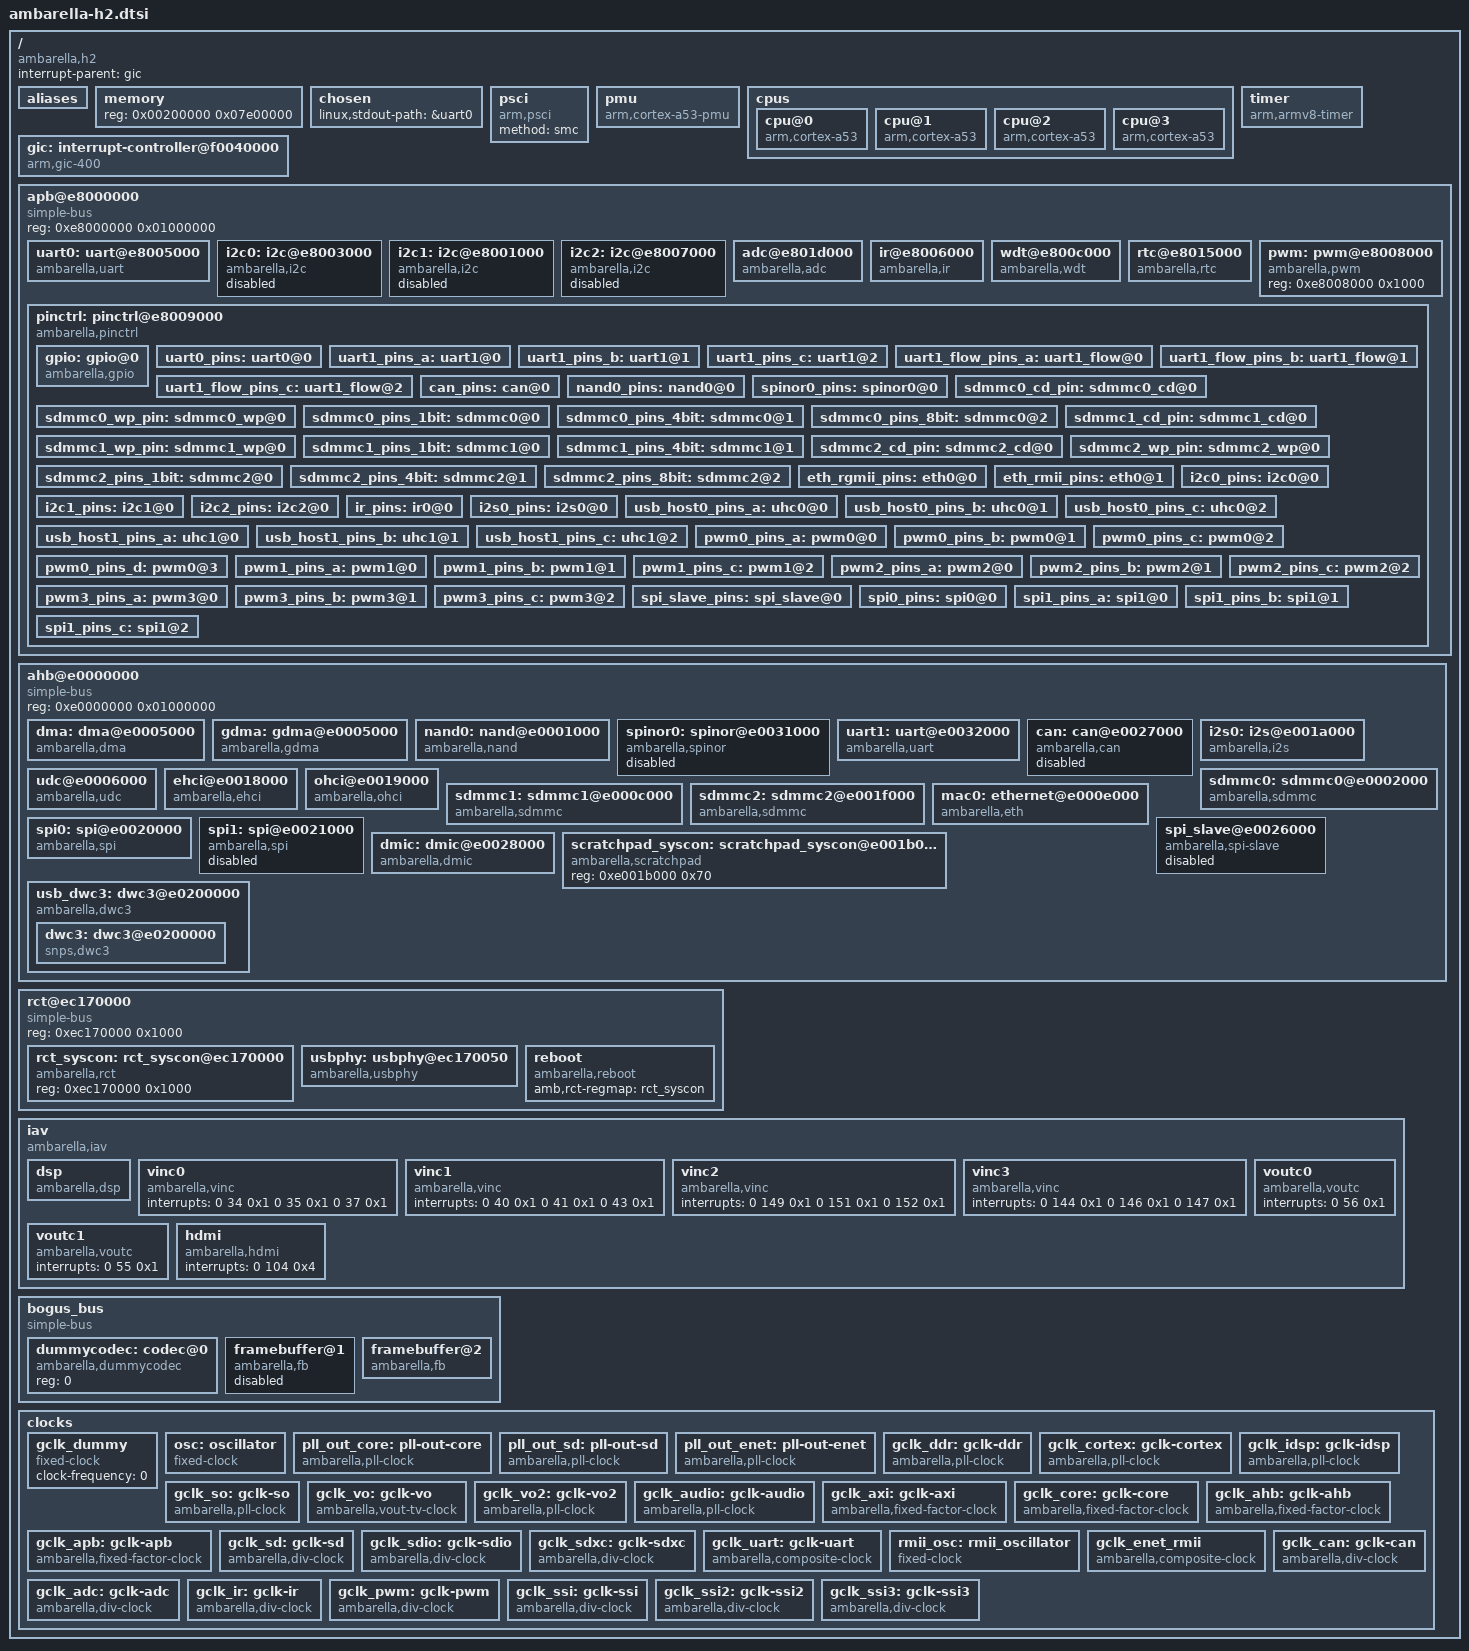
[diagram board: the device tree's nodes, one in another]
/*
 * Copyright (C) 2013 Ambarella,Inc. - http://www.ambarella.com/
 * Author: Cao Rongrong <rrcao@ambarella.com>
 *
 * This program is free software; you can redistribute it and/or modify
 * it under the terms of the GNU General Public License version 2 as
 * published by the Free Software Foundation.
 */

/ {
	compatible = "ambarella,h2";
	interrupt-parent = <&gic>;
	#address-cells = <1>;
	#size-cells = <1>;

	aliases {
		serial0 = &uart0;
		serial1 = &uart1;
		nand = &nand0;
		spinor = &spinor0;
		sd0 = &sdmmc0;
		sd1 = &sdmmc1;
		sd2 = &sdmmc2;
		i2c0 = &i2c0;
		i2c1 = &i2c1;
		i2c2 = &i2c2;
		spi0 = &spi0;
		spi1 = &spi1;
		ethernet0 = &mac0;
	};

	/* the memory node will be overwritten in Amboot,
	 * here is just the default value. */
	memory {
		device_type = "memory";
		reg = <0x00200000 0x07e00000>; /* 126M */
	};

	chosen {
		linux,stdout-path = &uart0;
	};

	psci {
		compatible = "arm,psci";
		method = "smc";
	};

	pmu {
		compatible = "arm,cortex-a53-pmu";
		interrupts = <0 15 0x4>,
			     <0 31 0x4>,
			     <0 114 0x4>,
			     <0 115 0x4>;
	};

	cpus {
		#address-cells = <1>;
		#size-cells = <0>;
		amb,core-div = <1>;
		clock-latency = <100000>;
		/* the highest frequency is gotten in runtime */
		cpufreq_tbl = < /*core_clk	cortex_clk*/
				24000		96000
				108000		504000>;

		cpu@0 {
			compatible = "arm,cortex-a53", "arm,armv8";
			device_type = "cpu";
			reg = <0x0>;
			enable-method = "spin-table";
			cpu-release-addr = <0 0x00000000>;
		};

		cpu@1 {
			compatible = "arm,cortex-a53", "arm,armv8";
			device_type = "cpu";
			reg = <0x1>;
			enable-method = "spin-table";
			cpu-release-addr = <0 0x00000000>;
		};

		cpu@2 {
			compatible = "arm,cortex-a53", "arm,armv8";
			device_type = "cpu";
			reg = <0x2>;
			enable-method = "spin-table";
			cpu-release-addr = <0 0x00000000>;
		};

		cpu@3 {
			compatible = "arm,cortex-a53", "arm,armv8";
			device_type = "cpu";
			reg = <0x3>;
			enable-method = "spin-table";
			cpu-release-addr = <0 0x00000000>;
		};
	};

	gic: interrupt-controller@f0040000 {
		compatible = "arm,gic-400";
		#interrupt-cells = <3>;
		#address-cells = <0>;
		interrupt-controller;
		reg = <0xf0041000 0x1000>,	/* GIC Dist */
		      <0xf0042000 0x2000>,	/* GIC CPU */
		      /* following are not used if no virtulization
		      <0xf0044000 0x2000>,	/* GIC VCPU Control */
		      <0xf0046000 0x2000>;	/* GIC VCPU */
		interrupts = <1 9 0xf04>;	/* GIC Maintenence IRQ */
	};

	timer {
		compatible = "arm,armv8-timer";
		interrupts = <1 13 0xf08>,	/* Secure Phys IRQ */
			     <1 14 0xf08>,	/* Non-secure Phys IRQ */
			     <1 11 0xf08>,	/* Virt IRQ */
			     <1 10 0xf08>;	/* Hyp IRQ */
	};

	apb@e8000000 {	/* APB */
		compatible = "simple-bus";
		#address-cells = <1>;
		#size-cells = <1>;
		reg = <0xe8000000 0x01000000>;
		ranges;

		uart0: uart@e8005000 {
			compatible = "ambarella,uart";
			reg = <0xe8005000 0x1000>;
			interrupts = <0 108 0x4>;
			pinctrl-names = "default";
			pinctrl-0 = <&uart0_pins>;
			clocks = <&gclk_uart>;
			status = "ok";
			/* amb,tx-fifo-fix; */
		};

		i2c0: i2c@e8003000 {
			compatible = "ambarella,i2c";
			#address-cells = <1>;
			#size-cells = <0>;
			reg = <0xe8003000 0x1000>;
			interrupts = <0 85 0x4>;
			pinctrl-names = "default";
			pinctrl-0 = <&i2c0_pins>;
			clocks = <&gclk_apb>;
			clock-frequency = <100000>;
			amb,i2c-class = <0x81>;
			status = "disabled";
	        };

		i2c1: i2c@e8001000 {
			compatible = "ambarella,i2c";
			#address-cells = <1>;
			#size-cells = <0>;
			reg = <0xe8001000 0x1000>;
			interrupts = <0 84 0x4>;
			pinctrl-names = "default";
			pinctrl-0 = <&i2c1_pins>;
			clocks = <&gclk_apb>;
			clock-frequency = <100000>;
			amb,i2c-class = <0x08>;
			status = "disabled";
	        };

		i2c2: i2c@e8007000 {
			compatible = "ambarella,i2c";
			#address-cells = <1>;
			#size-cells = <0>;
			reg = <0xe8007000 0x1000>;
			interrupts = <0 83 0x4>;
			pinctrl-names = "default";
			clocks = <&gclk_apb>;
			pinctrl-0 = <&i2c2_pins>;
			clock-frequency = <100000>;
			amb,i2c-class = <0x81>;
			status = "disabled";
	        };

		adc@e801d000 {
			compatible = "ambarella,adc";
			reg = <0xe801d000 0x1000>;
			interrupts = <0 103 0x4>;
			clock-frequency = <3000000>;
			clocks = <&gclk_adc>;
			amb,rct-regmap = <&rct_syscon>;
			amb,scaler-1v8 = <0x01>;
			amb,t2v-channel = <4>;
		};

		ir@e8006000 {
			compatible = "ambarella,ir";
			reg = <0xe8006000 0x1000>;
			interrupts = <0 86 0x4>;
			pinctrl-names = "default";
			pinctrl-0 = <&ir_pins>;
			clocks = <&gclk_ir>;
		};

		wdt@e800c000 {
			compatible = "ambarella,wdt";
			reg = <0xe800c000 0x1000>;
			amb,rct-regmap = <&rct_syscon>;
			/* interrupts = <0 105 0x4>; */
			timeout-sec = <15>;
		};

		rtc@e8015000 {
			compatible = "ambarella,rtc";
			reg = <0xe8015000 0x1000>;
			interrupts = <0 157 0x1>;
		};

		pwm: pwm@e8008000 {
			compatible = "ambarella,pwm";
			reg = <0xe8008000 0x1000>;
			#pwm-cells = <3>;
		};

		pinctrl: pinctrl@e8009000 {
			compatible = "ambarella,pinctrl", "simple-bus";
			#address-cells = <1>;
			#size-cells = <0>;
			reg = <0xe8009000 0x1000>,
			      <0xe800a000 0x1000>,
			      <0xe800e000 0x1000>,
			      <0xe8010000 0x1000>,
			      <0xe8011000 0x1000>,
			      <0xe8016000 0x1000>,
			      <0xe8015080 0x24>,
			      <0xec170314 0x20>;
			reg-names = "gpio0", "gpio1", "gpio2", "gpio3", "gpio4",
				    "iomux", "pad", "ds";
			#gpio-range-cells = <3>;

			gpio: gpio@0 {
				compatible = "ambarella,gpio";
				/* gpio interrupts to gic */
				interrupts = <0 124 0x4>,
					     <0 123 0x4>,
					     <0 122 0x4>,
					     <0 121 0x4>,
					     <0 120 0x4>;
				gpio-controller;
				#gpio-cells = <2>;
				gpio-ranges = <&pinctrl 0 0 160>;
				interrupt-controller;
				#interrupt-cells = <2>;
			};

			uart0_pins: uart0@0 {
				reg = <0>;
				amb,pinmux-ids = <0x101f 0x1020>;
			};

			uart1_pins_a: uart1@0 {
				reg = <0>;
				amb,pinmux-ids = <0x2008 0x2009>;
			};

			uart1_pins_b: uart1@1 {
				reg = <1>;
				amb,pinmux-ids = <0x301a 0x3017>;
			};

			uart1_pins_c: uart1@2 {
				reg = <2>;
				amb,pinmux-ids = <0x107b 0x107c>;
			};

			uart1_flow_pins_a: uart1_flow@0 {
				reg = <0>;
				amb,pinmux-ids = <0x200a 0x200b>;
			};

			uart1_flow_pins_b: uart1_flow@1 {
				reg = <1>;
				amb,pinmux-ids = <0x3018 0x3019>;
			};

			uart1_flow_pins_c: uart1_flow@2 {
				reg = <2>;
				amb,pinmux-ids = <0x107d 0x107e>;
			};

			can_pins: can@0 {
				reg = <0>;
				amb,pinmux-ids = <0x307d 0x307e>;
			};

			nand0_pins: nand0@0 {
				reg = <0>;
				amb,pinmux-ids = <0x2038 0x2039 0x203a 0x203f
						  0x2040 0x2041 0x2042 0x2043
						  0x2044 0x2045 0x2046 0x2047
						  0x2048 0x2049 0x204a>;
			};

			spinor0_pins: spinor0@0 {
				reg = <0>;
				amb,pinmux-ids = <0x3039 0x303a 0x303f 0x3040
						  0x3041 0x3042 0x3043 0x3044
						  0x3045 0x3046 0x3047 0x3048
						  0x3049>;
			};

			sdmmc0_cd_pin: sdmmc0_cd@0 {
				reg = <0>;
				amb,pinmux-ids = <0x203d>;
			};

			sdmmc0_wp_pin: sdmmc0_wp@0 {
				reg = <0>;
				amb,pinmux-ids = <0x203e>;
			};

			sdmmc0_pins_1bit: sdmmc0@0 {
				reg = <0>;
				amb,pinmux-ids = <0x203b 0x203c 0x204b>;
			};

			sdmmc0_pins_4bit: sdmmc0@1 {
				reg = <1>;
				amb,pinmux-ids = <0x203b 0x203c 0x204b
						  0x204c 0x204d 0x204e>;
			};

			sdmmc0_pins_8bit: sdmmc0@2 {
				reg = <2>;
				amb,pinmux-ids = <0x203b 0x203c 0x204b 0x204c 0x204d
						  0x204e 0x204f 0x2050 0x2051 0x2052>;
			};

			sdmmc1_cd_pin: sdmmc1_cd@0 {
				reg = <0>;
				amb,pinmux-ids = <0x5002>;
			};

			sdmmc1_wp_pin: sdmmc1_wp@0 {
				reg = <0>;
				amb,pinmux-ids = <0x5003>;
			};

			sdmmc1_pins_1bit: sdmmc1@0 {
				reg = <0>;
				amb,pinmux-ids = <0x5000 0x5001 0x5004>;
			};

			sdmmc1_pins_4bit: sdmmc1@1 {
				reg = <1>;
				amb,pinmux-ids = <0x5000 0x5001 0x5004
						  0x5005 0x5006 0x5007>;
			};

			sdmmc2_cd_pin: sdmmc2_cd@0 {
				reg = <0>;
				amb,pinmux-ids = <0x2059>;
			};

			sdmmc2_wp_pin: sdmmc2_wp@0 {
				reg = <0>;
				amb,pinmux-ids = <0x205a>;
			};

			sdmmc2_pins_1bit: sdmmc2@0 {
				reg = <0>;
				amb,pinmux-ids = <0x2053 0x2054 0x2055>;
			};

			sdmmc2_pins_4bit: sdmmc2@1 {
				reg = <1>;
				amb,pinmux-ids = <0x2053 0x2054 0x2055
						  0x2056 0x2057 0x2058>;
			};

			sdmmc2_pins_8bit: sdmmc2@2 {
				reg = <2>;
				amb,pinmux-ids = <0x2053 0x2054 0x2055 0x2056 0x2057
						  0x2058 0x205b 0x205c 0x205d 0x205e>;
			};

			eth_rgmii_pins: eth0@0 {
				reg = <0>;
				amb,pinmux-ids = <0x4032 0x4033 0x4034 0x4035
						  0x4036 0x4037 0x4026 0x4030
						  0x4028 0x4029 0x402a 0x402b
						  0x402c 0x402d 0x402e 0x402f>;
			};

			eth_rmii_pins: eth0@1 {
				reg = <1>;
				amb,pinmux-ids = <0x3032 0x3033 0x3035 0x3034
					0x3036 0x3037 0x3026 0x3030
					0x3028 0x3029 0x302c 0x302d>;
			};

			i2c0_pins: i2c0@0 {
				reg = <0>;
				amb,pinmux-ids = <0x100f 0x1010>;
			};

			i2c1_pins: i2c1@0 {
				reg = <0>;
				amb,pinmux-ids = <0x1011 0x1012>;
			};

			i2c2_pins: i2c2@0 {
				reg = <0>;
				amb,pinmux-ids = <0x1013 0x1014>;
			};

			ir_pins: ir0@0 {
				reg = <0>;
				amb,pinmux-ids = <0x1015>;
			};

			i2s0_pins: i2s0@0 {
				reg = <0>;
				amb,pinmux-ids = <0x1021 0x1022 0x1023 0x1024 0x1025>;
			};

			usb_host0_pins_a: uhc0@0 { /* USB0: host/device configurable */
				reg = <0>;
				amb,pinmux-ids = <0x3008 0x300a>;
			};

			usb_host0_pins_b: uhc0@1 { /* USB0: host/device configurable */
				reg = <1>;
				amb,pinmux-ids = <0x301b 0x301d>;
			};

			usb_host0_pins_c: uhc0@2 { /* USB0: host/device configurable */
				reg = <2>;
				amb,pinmux-ids = <0x505b 0x505d>;
			};

			usb_host1_pins_a: uhc1@0 { /* USB1: host only */
				reg = <0>;
				amb,pinmux-ids = <0x3009 0x300b>;
			};

			usb_host1_pins_b: uhc1@1 { /* USB1: host only */
				reg = <1>;
				amb,pinmux-ids = <0x301c 0x301e>;
			};

			usb_host1_pins_c: uhc1@2 { /* USB1: host only */
				reg = <2>;
				amb,pinmux-ids = <0x505c 0x505e>;
			};

			pwm0_pins_a: pwm0@0 {
				reg = <0>;
				amb,pinmux-ids = <0x3000>;
			};

			pwm0_pins_b: pwm0@1 {
				reg = <1>;
				amb,pinmux-ids = <0x5008>;
			};

			pwm0_pins_c: pwm0@2 {
				reg = <2>;
				amb,pinmux-ids = <0x5028>;
			};

			pwm0_pins_d: pwm0@3 {
				reg = <3>;
				amb,pinmux-ids = <0x107a>;
			};

			pwm1_pins_a: pwm1@0 {
				reg = <0>;
				amb,pinmux-ids = <0x3001>;
			};

			pwm1_pins_b: pwm1@1 {
				reg = <1>;
				amb,pinmux-ids = <0x5009>;
			};

			pwm1_pins_c: pwm1@2 {
				reg = <2>;
				amb,pinmux-ids = <0x5029>;
			};

			pwm2_pins_a: pwm2@0 {
				reg = <0>;
				amb,pinmux-ids = <0x3002>;
			};

			pwm2_pins_b: pwm2@1 {
				reg = <1>;
				amb,pinmux-ids = <0x500a>;
			};

			pwm2_pins_c: pwm2@2 {
				reg = <2>;
				amb,pinmux-ids = <0x502a>;
			};

			pwm3_pins_a: pwm3@0 {
				reg = <0>;
				amb,pinmux-ids = <0x3003>;
			};

			pwm3_pins_b: pwm3@1 {
				reg = <1>;
				amb,pinmux-ids = <0x500b>;
			};

			pwm3_pins_c: pwm3@2 {
				reg = <2>;
				amb,pinmux-ids = <0x502b>;
			};

			spi_slave_pins: spi_slave@0 {
				reg = <0>;
				amb,pinmux-ids = <0x101b 0x101c 0x101d 0x101e>;
			};

			spi0_pins: spi0@0 {
				reg = <0>;
				amb,pinmux-ids = <0x1016 0x1017 0x1018>;
			};

			spi1_pins_a: spi1@0 {
				reg = <0>;
				amb,pinmux-ids = <0x2000 0x2001 0x2002>;
			};

			spi1_pins_b: spi1@1 {
				reg = <1>;
				amb,pinmux-ids = <0x201b 0x201c 0x201d>;
			};

			spi1_pins_c: spi1@2 {
				reg = <2>;
				amb,pinmux-ids = <0x207b 0x207c 0x207d>;
			};
		};
	};

	ahb@e0000000 {	/* AHB */
		compatible = "simple-bus";
		#address-cells = <1>;
		#size-cells = <1>;
		reg = <0xe0000000 0x01000000>;
		ranges;

		dma: dma@e0005000 {
			compatible = "ambarella,dma";
			reg = <0xe0005000 0x1000>;
			interrupts = <0 69 0x4>;
			#dma-cells = <1>;
			dma-channels = <8>;
			dma-requests = <14>;
			amb,scr-regmap = <&scratchpad_syscon>;
			/* support pause/resume/stop */
			amb,support-prs;
		};

		gdma: gdma@e0005000 {
			compatible = "ambarella,gdma";
			reg = <0xe0015000 0x400>;
			interrupts = <0 74 0x1>;
		};

		nand0: nand@e0001000 {
			compatible = "ambarella,nand";
			#address-cells = <1>;
			#size-cells = <1>;
			reg = <0xe0001000 0x1000>,	/* fio reg address */
			      <0xe0012000 0x1000>,	/* fdma reg address */
			      <0xe0000000 0x4>;		/* fifo base */
			interrupts = <0 72 0x4>,	/* fio_cmd_irq */
				     <0 73 0x4>,	/* fio_dma_irq */
				     <0 70 0x4>;	/* fdma_irq */
			amb,rct-regmap = <&rct_syscon>;
			pinctrl-names = "default";
			pinctrl-0 = <&nand0_pins>;
			clocks = <&gclk_core>;
			nand-on-flash-bbt;
			amb,enable-wp;
			/* amb,soft-ecc = <1>; */
		};

		spinor0: spinor@e0031000 {
			compatible = "ambarella,spinor";
			reg = <0xe0031000 0x2ff>, /* spi nor controller */
			      <0xe0005300 0x20>;  /* dma reg */
			pinctrl-names = "default";
			pinctrl-0 = <&spinor0_pins>;
			status = "disabled";
		};

		uart1: uart@e0032000 {
			compatible = "ambarella,uart";
			reg = <0xe0032000 0x1000>;
			interrupts = <0 82 0x4>;
			pinctrl-names = "default";
			pinctrl-0 = <&uart1_pins_c &uart1_flow_pins_c>;
			clocks = <&gclk_uart>;
			status = "ok";
			amb,msr-used;	/* use Modem Status Register */
			amb,txdma-used;
			amb,rxdma-used;
			/* amb,tx-fifo-fix; */
			/* need to select pinctrl setup in board dts */
		};

		can: can@e0027000 {
			compatible = "ambarella,can";
			reg = <0xe0027000 0xc00>;
			interrupts = <0 64 0x4>;
			pinctrl-names = "default";
			pinctrl-0 = <&can_pins>;
			clocks = <&gclk_can>;
			status = "disabled";
		};

		i2s0: i2s@e001a000 {
			compatible = "ambarella,i2s";
			#sound-dai-cells = <0>;
			reg = <0xe001a000 0x1000>;
			pinctrl-names = "default";
			pinctrl-0 = <&i2s0_pins>;
			amb,i2s-channels = <2>;
			amb,default-mclk = <12288000>;
			dmas = <&dma 10>, <&dma 11>;
			dma-names = "tx", "rx";
		};

		udc@e0006000 {
			compatible = "ambarella,udc";
			reg = <0xe0006000 0x2000>;
			interrupts = <0 68 0x4>;
			amb,rct-regmap = <&rct_syscon>;
			amb,scr-regmap = <&scratchpad_syscon>;
			amb,usbphy = <&usbphy>;
		};

		ehci@e0018000 {
			compatible = "ambarella,ehci";
			reg = <0xe0018000 0x1000>;
			interrupts = <0 66 0x4>;
			amb,usbphy = <&usbphy>;
		};

		ohci@e0019000 {
			compatible = "ambarella,ohci";
			reg = <0xe0019000 0x1000>;
			interrupts = <0 67 0x4>;
			amb,usbphy = <&usbphy>;
		};

		sdmmc0: sdmmc0@e0002000 {
			compatible = "ambarella,sdmmc";
			#address-cells = <1>;
			#size-cells = <0>;
			reg = <0xe0002000 0x1000>,
			      <0xec1704c0 0x8>,  /* phy timing */
			      <0xec170664 0x4>;  /* sbc reg address */
			interrupts = <0 77 0x4>;
			pinctrl-names = "default";
			pinctrl-0 = <&sdmmc0_pins_8bit &sdmmc0_cd_pin &sdmmc0_wp_pin>;
			clocks = <&gclk_sd>;
			amb,switch-vol-tmo = <100>; /* in millisecond */
			max-frequency = <120000000>;
			bus-width = <8>;
			cap-sdio-irq;
		};

		sdmmc1: sdmmc1@e000c000 {
			compatible = "ambarella,sdmmc";
			#address-cells = <1>;
			#size-cells = <0>;
			reg = <0xe000c000 0x1000>;
			interrupts = <0 76 0x4>;
			pinctrl-names = "default";
			pinctrl-0 = <&sdmmc1_pins_4bit &sdmmc1_cd_pin &sdmmc1_wp_pin>;
			clocks = <&gclk_sdio>;
			amb,switch_vol_tmo = <100>; /* in millisecond */
			max-frequency = <50000000>;
			bus-width = <4>;
			cap-sdio-irq;
		};

		sdmmc2: sdmmc2@e001f000 { /* SDXC rather than SDIO */
			compatible = "ambarella,sdmmc";
			#address-cells = <1>;
			#size-cells = <0>;
			reg = <0xe001f000 0x1000>,
			      <0xec1704c8 0x8>,  /* phy timing */
			      <0xec170668 0x4>;  /* sbc reg address */
			interrupts = <0 75 0x4>;
			pinctrl-names = "default";
			pinctrl-0 = <&sdmmc2_pins_8bit &sdmmc2_cd_pin &sdmmc2_wp_pin>;
			clocks = <&gclk_sdxc>;
			amb,switch-vol-tmo = <100>; /* in millisecond */
			max-frequency = <100000000>;
			bus-width = <8>;
			cap-sdio-irq;
		};

		mac0: ethernet@e000e000 {
			compatible = "ambarella,eth";
			#address-cells = <1>;
			#size-cells = <0>;
			reg = <0xe000e000 0x2000>;
			interrupts = <0 65 0x4>;
			pinctrl-names = "default";
			pinctrl-0 = <&eth_rgmii_pins>;
			phy-mode = "rgmii";
			amb,rct-regmap = <&rct_syscon>;
			amb,scr-regmap = <&scratchpad_syscon>;
			amb,tx-ring-size = <32>;
			amb,rx-ring-size = <64>;
			amb,ipc-tx;
			amb,ipc-rx;
			amb,enhance;
			amb,tx-clk-invert;
		};

		spi0: spi@e0020000 {
			compatible = "ambarella,spi";
			#address-cells = <1>;
			#size-cells = <0>;
			reg = <0xe0020000 0x1000>;
			interrupts = <0 80 0x4>;
			pinctrl-names = "default";
			pinctrl-0 = <&spi0_pins>;
			amb,clk-freq = <54000000>;
			/* amb,dma-used; */
			dmas = <&dma 0>, <&dma 1>;
			dma-names = "tx", "rx";
		};

		spi1: spi@e0021000 {
			compatible = "ambarella,spi";
			#address-cells = <1>;
			#size-cells = <0>;
			reg = <0xe0021000 0x1000>;
			interrupts = <0 79 0x4>;
			pinctrl-names = "default";
			pinctrl-0 = <&spi1_pins_a>;
			amb,clk-freq = <54000000>;
			status = "disabled";
		};

		spi_slave@e0026000 {
			compatible = "ambarella,spi-slave";
			reg = <0xe0026000 0x1000>;
			interrupts = <0 81 0x4>;
			pinctrl-names = "default";
			pinctrl-0 = <&spi_slave_pins>;
			status = "disabled";
		};

		dmic: dmic@e0028000 {
			compatible = "ambarella,dmic";
			reg = <0xe0028000 0x1000>;
			amb,scr-regmap = <&scratchpad_syscon>;
			#sound-dai-cells = <0>;
		};

		scratchpad_syscon: scratchpad_syscon@e001b000 {
			compatible = "ambarella,scratchpad", "syscon";
			reg = <0xe001b000 0x70>;
		};

		usb_dwc3: dwc3@e0200000 {
			compatible	= "ambarella,dwc3";
			amb,rct-regmap = <&rct_syscon>;
			amb,scr-regmap = <&scratchpad_syscon>;
			#address-cells	= <1>;
			#size-cells	= <1>;
			ranges;

			status = "ok";

			dwc3: dwc3@e0200000 {
				compatible	= "snps,dwc3";
				reg		= <0xe0200000 0xcfff>;
				interrupts	=  <0 61 0x4>;
				dr_mode		= "peripheral";
				usb-phy		= <&usbphy>, <&usbphy>;
			};
		};
	};

	rct@ec170000 {
		compatible = "simple-bus";
		#address-cells = <1>;
		#size-cells = <1>;
		reg = <0xec170000 0x1000>;
		ranges;

		rct_syscon: rct_syscon@ec170000 {
			compatible = "ambarella,rct", "syscon";
			reg = <0xec170000 0x1000>;
		};

		usbphy: usbphy@ec170050 {
			compatible = "ambarella,usbphy";
			reg = <0xec170050 0x4 0xe001b00c 0x4 0xec1702c0 0x4>;
			amb,host-phy-num = <2>;
			amb,owner-mask;
			amb,owner-invert;
		};

		reboot {
			compatible = "ambarella,reboot";
			amb,rct-regmap = <&rct_syscon>;
		};
	};

	iav {
		compatible = "ambarella,iav", "ambpriv-bus";
		#address-cells = <1>;
		#size-cells = <1>;

		/* node for dsp controller */
		dsp {
			compatible = "ambarella,dsp";
			interrupts = <0 46 0x1 0 47 0x1 0 48 0x1 0 49 0x1 0 51 0x1>;
			interrupt-names = "vdsp", "vin_main", "venc", "vcap", "vin_pip";
		};

		/* node for vin0 controller */
		vinc0 {
			compatible = "ambarella,vinc";
			interrupts = <0 34 0x1 0 35 0x1 0 37 0x1>;
			interrupt-names = "idsp", "idsp_sof", "idsp_last_pixel";
		};

		/* node for vin1 controller */
		vinc1 {
			compatible = "ambarella,vinc";
			interrupts = <0 40 0x1 0 41 0x1 0 43 0x1>;
			interrupt-names = "idsp", "idsp_sof", "idsp_last_pixel";
		};

		/* node for vin2 controller */
		vinc2 {
			compatible = "ambarella,vinc";
			interrupts = <0 149 0x1 0 151 0x1 0 152 0x1>;
			interrupt-names = "idsp", "idsp_sof", "idsp_last_pixel";
		};

		/* node for vin3 controller */
		vinc3 {
			compatible = "ambarella,vinc";
			interrupts = <0 144 0x1 0 146 0x1 0 147 0x1>;
			interrupt-names = "idsp", "idsp_sof", "idsp_last_pixel";
		};

		/* node for vout0 controller */
		voutc0 {
			compatible = "ambarella,voutc";
			interrupts = <0 56 0x1>;
			interrupt-names = "vout0";
		};

		/* node for vout1 controller */
		voutc1 {
			compatible = "ambarella,voutc";
			interrupts = <0 55 0x1>;
			interrupt-names = "vout1";
		};

		/* node for hdmi controller */
		hdmi {
			compatible = "ambarella,hdmi";
			interrupts = <0 104 0x4>;
			interrupt-names = "hdmi";
		};
	};

	bogus_bus {
		compatible = "simple-bus";
		#address-cells = <1>;
		#size-cells = <0>;

		dummycodec: codec@0 {
			compatible = "ambarella,dummycodec";
			reg = <0>;
			#sound-dai-cells = <0>;
		};

		framebuffer@1 {
			compatible = "ambarella,fb";
			amb,vout-id = <0>;
			amb,format = "rgb565";
			status = "disabled";
		};

		framebuffer@2 {
			compatible = "ambarella,fb";
			amb,vout-id = <1>;
			amb,format = "rgb565";
		};
	};

	clocks {
		#address-cells = <1>;
		#size-cells = <1>;
		ranges;

		/*
		 * This is a dummy clock, to be used as placeholder on other
		 * mux clocks when corresponding bits in register don't represent
		 * real parent clock.
		 */
		gclk_dummy: gclk_dummy {
			#clock-cells = <0>;
			compatible = "fixed-clock";
			clock-frequency = <0>;
		};

		/*
		 * Fixed 24MHz oscillator inputs to SoC
		 */
		osc: oscillator {
			compatible = "fixed-clock";
			#clock-cells = <0>;
			clock-frequency = <24000000>;
			clock-output-names = "osc";
		};

		pll_out_core: pll-out-core {
			#clock-cells = <0>;
			compatible = "ambarella,pll-clock";
			reg = <0xec170000 4>,
			      <0xec170004 4>,
			      <0xec170100 4>,
			      <0xec170104 4>,
			      <0x00000000 0>,
			      <0x00000000 0>;
			clocks = <&osc>;
			clock-output-names = "pll_out_core";
		};

		pll_out_sd: pll-out-sd {
			#clock-cells = <0>;
			compatible = "ambarella,pll-clock";
			reg = <0xec1704ac 4>,
			      <0xec1704b0 4>,
			      <0xec1704b4 4>,
			      <0xec1704b8 4>,
			      <0x00000000 0>,
			      <0x00000000 0>;
			clocks = <&osc>;
			clock-output-names = "pll_out_sd";
			amb,frac-mode;
		};

		pll_out_enet: pll-out-enet {
			#clock-cells = <0>;
			compatible = "ambarella,pll-clock";
			reg = <0xec170520 4>,
			      <0xec170524 4>,
			      <0xec170528 4>,
			      <0xec17052c 4>,
			      <0x00000000 0>,
			      <0x00000000 0>;
			clocks = <&osc>;
			clock-output-names = "pll_out_enet";
			amb,frac-mode;
		};

		gclk_ddr: gclk-ddr {
			#clock-cells = <0>;
			compatible = "ambarella,pll-clock";
			reg = <0xec1700dc 4>,
			      <0xec1700e0 4>,
			      <0xec170110 4>,
			      <0xec170114 4>,
			      <0x00000000 0>,
			      <0x00000000 0>;
			clocks = <&osc>;
			clock-output-names = "gclk_ddr";
			amb,fix-divider = <2>;
		};

		gclk_cortex: gclk-cortex {
			#clock-cells = <0>;
			compatible = "ambarella,pll-clock";
			reg = <0xec170264 4>,
			      <0xec170268 4>,
			      <0xec17026c 4>,
			      <0xec170270 4>,
			      <0x00000000 0>,
			      <0x00000000 0>;
			clocks = <&osc>;
			clock-output-names = "gclk_cortex";
		};

		gclk_idsp: gclk-idsp {
			#clock-cells = <0>;
			compatible = "ambarella,pll-clock";
			reg = <0xec1700e4 4>,
			      <0xec1700e8 4>,
			      <0xec170108 4>,
			      <0xec17010c 4>,
			      <0x00000000 0>,
			      <0xec1701f4 4>;
			clocks = <&osc>;
			clock-output-names = "gclk_idsp";
			amb,extra-post-scaler;
		};

		gclk_so: gclk-so {
			#clock-cells = <0>;
			compatible = "ambarella,pll-clock";
			reg = <0xec170024 4>,
			      <0xec170028 4>,
			      <0xec17011c 4>,
			      <0xec170120 4>,
			      <0xec17004c 4>,
			      <0xec170030 4>;
			clocks = <&osc>;
			clock-output-names = "gclk_so";
			assigned-clocks = <&gclk_so>;
			assigned-clock-rates = <24000000>;
			amb,extra-pre-scaler;
			amb,extra-post-scaler;
			amb,frac-mode;
		};

		gclk_vo: gclk-vo { /* for tv */
			#clock-cells = <0>;
			compatible = "ambarella,vout-tv-clock";
			reg = <0xec170164 4>,
			      <0xec170168 4>,
			      <0xec170150 4>,
			      <0xec170154 4>,
			      <0xec170170 4>,
			      <0xec170008 0>;
			clocks = <&osc>;
			clock-output-names = "gclk_vo";
			assigned-clocks = <&gclk_vo>;
			assigned-clock-rates = <24000000>;
			amb,extra-pre-scaler;
			amb,frac-mode;
			amb,fix-divider = <10>;
			amb,ctrl2-val = <0x3f700900>;
			amb,ctrl3-val = <0x00068306>;
			amb,min-vco = <2500>; /* in MHz */
		};

		gclk_vo2: gclk-vo2 { /* for lcd */
			#clock-cells = <0>;
			compatible = "ambarella,pll-clock";
			reg = <0xec1700c0 4>,
			      <0xec1700c4 4>,
			      <0xec17013c 4>,
			      <0xec170140 4>,
			      <0xec1700c8 4>,
			      <0xec1700cc 4>;
			clocks = <&osc>;
			clock-output-names = "gclk_vo2";
			assigned-clocks = <&gclk_vo2>;
			assigned-clock-rates = <24000000>;
			amb,extra-pre-scaler;
			amb,extra-post-scaler;
			amb,frac-mode;
		};

		gclk_audio: gclk-audio {
			#clock-cells = <0>;
			compatible = "ambarella,pll-clock";
			reg = <0xec170054 4>,
			      <0xec170058 4>,
			      <0xec170124 4>,
			      <0xec17012c 4>,
			      <0xec170060 4>,
			      <0xec17005c 4>;
			clocks = <&osc>;
			clock-output-names = "gclk_audio";
			assigned-clocks = <&gclk_audio>;
			assigned-clock-rates = <12288000>;
			amb,extra-pre-scaler;
			amb,extra-post-scaler;
			amb,frac-mode;
		};

		gclk_axi: gclk-axi {
			#clock-cells = <0>;
			compatible = "ambarella,fixed-factor-clock";
			clocks = <&gclk_cortex>;
			clock-output-names = "gclk_axi";
			clock-mult = <1>;
			clock-div = <3>;
		};

		gclk_core: gclk-core {
			#clock-cells = <0>;
			compatible = "ambarella,fixed-factor-clock";
			clocks = <&pll_out_core>;
			clock-output-names = "gclk_core";
			clock-mult = <1>;
			clock-div = <1>;
		};

		gclk_ahb: gclk-ahb {
			#clock-cells = <0>;
			compatible = "ambarella,fixed-factor-clock";
			clocks = <&gclk_core>;
			clock-output-names = "gclk_ahb";
			clock-mult = <1>;
			clock-div = <2>;
		};

		gclk_apb: gclk-apb {
			#clock-cells = <0>;
			compatible = "ambarella,fixed-factor-clock";
			clocks = <&gclk_ahb>;
			clock-output-names = "gclk_apb";
			clock-mult = <1>;
			clock-div = <2>;
		};

		gclk_sd: gclk-sd {
			#clock-cells = <0>;
			compatible = "ambarella,div-clock";
			reg = <0xec17000c 4>;
			clocks = <&pll_out_sd>;
			clock-output-names = "gclk_sd";
			amb,div-width = <16>;
			amb,div-shift = <0>;
		};

		gclk_sdio: gclk-sdio {
			#clock-cells = <0>;
			compatible = "ambarella,div-clock";
			reg = <0xec170430 4>;
			clocks = <&pll_out_sd>;
			clock-output-names = "gclk_sdio";
			amb,div-width = <16>;
			amb,div-shift = <0>;
		};

		gclk_sdxc: gclk-sdxc {
			#clock-cells = <0>;
			compatible = "ambarella,div-clock";
			reg = <0xec170434 4>;
			clocks = <&pll_out_sd>;
			clock-output-names = "gclk_sdxc";
			amb,div-width = <16>;
			amb,div-shift = <0>;
		};

		gclk_uart: gclk-uart {
			#clock-cells = <0>;
			compatible = "ambarella,composite-clock";
			reg = <0xec170038 4>, <0xec1701c8 4>;
			clocks = <&osc>, <&gclk_core>, <&gclk_dummy>, <&gclk_idsp>;
			clock-output-names = "gclk_uart";
			assigned-clocks = <&gclk_uart>;
			assigned-clock-parents = <&osc>;
			amb,div-width = <24>;
			amb,div-shift = <0>;
		};

		rmii_osc: rmii_oscillator {
			compatible = "fixed-clock";
			#clock-cells = <0>;
			clock-frequency = <25000000>;
			clock-output-names = "rmii_osc";
		};

		gclk_enet_rmii: gclk_enet_rmii {
			#clock-cells = <0>;
			compatible = "ambarella,composite-clock";
			reg = <0xec170534 4>, <0xec1706b8 4>;
			clocks = <&rmii_osc>, <&pll_out_enet>;
			amb,fix-divider = <2>;
			amb,div-width = <4>;
			amb,div-shift = <4>;
			amb,div-plus;
		};

		gclk_can: gclk-can {
			#clock-cells = <0>;
			compatible = "ambarella,div-clock";
			reg = <0xec170570 4>;
			clocks = <&osc>;
			clock-output-names = "gclk_can";
			amb,div-width = <24>;
			amb,div-shift = <0>;
		};

		gclk_adc: gclk-adc {
			#clock-cells = <0>;
			compatible = "ambarella,div-clock";
			reg = <0xec17009c 4>;
			clocks = <&osc>;
			clock-output-names = "gclk_adc";
			amb,div-width = <16>;
			amb,div-shift = <0>;
		};

		gclk_ir: gclk-ir {
			#clock-cells = <0>;
			compatible = "ambarella,div-clock";
			reg = <0xec170044 4>;
			clocks = <&osc>;
			clock-output-names = "gclk_ir";
			amb,div-width = <24>;
			amb,div-shift = <0>;
		};

		gclk_pwm: gclk-pwm {
			#clock-cells = <0>;
			compatible = "ambarella,div-clock";
			reg = <0xec170084 4>;
			clocks = <&gclk_apb>;
			clock-output-names = "gclk_pwm";
			amb,div-width = <24>;
			amb,div-shift = <0>;
		};

		gclk_ssi: gclk-ssi {
			#clock-cells = <0>;
			compatible = "ambarella,div-clock";
			reg = <0xec17003c 4>;
			clocks = <&gclk_core>;
			clock-output-names = "gclk_ssi";
			amb,div-width = <24>;
			amb,div-shift = <0>;
		};

		gclk_ssi2: gclk-ssi2 {
			#clock-cells = <0>;
			compatible = "ambarella,div-clock";
			reg = <0xec1700ec 4>;
			clocks = <&gclk_core>;
			clock-output-names = "gclk_ssi2";
			amb,div-width = <24>;
			amb,div-shift = <0>;
		};

		gclk_ssi3: gclk-ssi3 {
			#clock-cells = <0>;
			compatible = "ambarella,div-clock";
			reg = <0xec170518 4>;
			clocks = <&pll_out_enet>;
			clock-output-names = "gclk_ssi3";
			amb,div-width = <24>;
			amb,div-shift = <0>;
		};
	};
};
